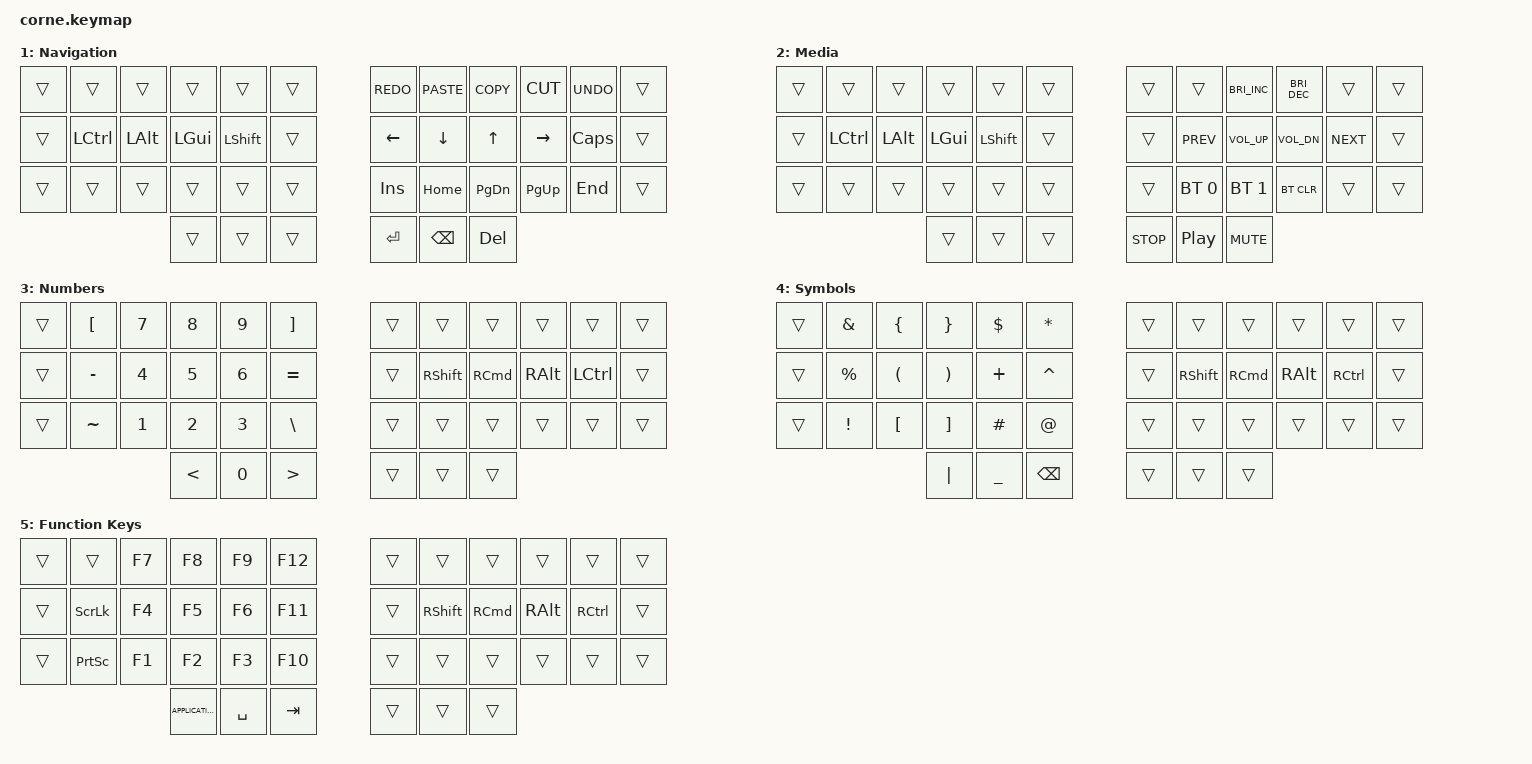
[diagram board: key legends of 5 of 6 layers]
/*
 * Copyright (c) 2020 The ZMK Contributors
 *
 * SPDX-License-Identifier: MIT
 */
// ZMK includes
#include <behaviors.dtsi>
#include <dt-bindings/zmk/bt.h>
#include <dt-bindings/zmk/keys.h>

// Define layers number
#define Base 0
#define Nav 1
#define Media 2
#define Num 3
#define Symbol 4
#define FN 5

/ {
    behaviors {
        // Positional Homerow mods
        // Homerow mods that prevent accidental activations when rolling keys,
        // such as when typing `st` or `ne` on colemak-dh layouts or `as` on
        // qwerty.
        //
        // Works by only allowing a mod to activate within tapping-term if
        // it's on the opposite side of the keyboard or on the same side thumb
        // keys.
        // Further optimization using urob's timerless homerow mods method:
        // https://github.com/urob/zmk-config#timeless-homerow-mods

        hm_l: homerow_mods_left {
            compatible = "zmk,behavior-hold-tap";
            #binding-cells = <3>;
            bindings = <&kp N &kp R &kp T>;

            flavor = "balanced";
            tapping-term-ms = <300>;
            quick-tap-ms = <175>;                // repeat on tap-into-hold
            require-prior-idle-ms = <150>;
            hold-trigger-key-positions = <13 14 15>;

        };

        hm_r: homerow_mods_right {
            compatible = "zmk,behavior-hold-tap";
            #binding-cells = <3>;
            bindings = <&kp A &kp E &kp I>;

            flavor = "balanced";
            tapping-term-ms = <300>;
            quick-tap-ms = <175>;
            require-prior-idle-ms = <150>;
            hold-trigger-key-positions = <20 21 22>;

        };

        // Positional Homerow mods for shift
        // Use faster tapping term and disable some features that may
        // cause false negatives.

        hm_shift_l: hm_shift_l {
            compatible = "zmk,behavior-hold-tap";
            #binding-cells = <1>;
            bindings = <&kp S>;

            flavor = "balanced";
            tapping-term-ms = <200>;
            quick-tap-ms = <175>;
            require-prior-idle-ms = <150>;
            hold-trigger-key-positions = <16>;

        };

        hm_shift_r: hm_shift_r {
            compatible = "zmk,behavior-hold-tap";
            #binding-cells = <1>;
            bindings = <&kp H>;

            flavor = "balanced";
            tapping-term-ms = <200>;
            quick-tap-ms = <175>;
            require-prior-idle-ms = <150>;
            hold-trigger-key-positions = <19>;

        };
    };

    keymap {
        compatible = "zmk,keymap";

        Base_layer {
            display-name = "Base";
            bindings = <
&kp ESC    &kp B          &kp L         &kp D         &kp W                &kp Z      &kp SQT      &kp F                &kp O         &kp U         &kp J          &kp DOUBLE_QUOTES
&kp CAPS   &hm_l LCTRL N  &hm_l LALT R  &hm_l LGUI T  &hm_shift_l LSHFT S  &kp G      &kp Y        &hm_shift_r RSHFT H  &hm_r RGUI A  &hm_r RALT E  &hm_r RCTRL I  &kp SINGLE_QUOTE
&kp GRAVE  &kp Q          &kp X         &kp M         &kp C                &kp V      &kp K        &kp P                &kp R         &kp COMMA     &kp SLASH      &kp SEMI
                                        &lt 2 ESCAPE  &lt 1 BACKSPACE      &kp TAB    &lt 4 ENTER  &lt 3 SPACE          &lt 5 DELETE
            >;
        };

        Nav_layer {
            display-name = "Navigation";
            bindings = <
&trans  &trans     &trans    &trans    &trans     &trans    &kp K_REDO  &kp K_PASTE    &kp K_COPY     &kp K_CUT    &kp K_UNDO  &trans
&trans  &kp LCTRL  &kp LALT  &kp LGUI  &kp LSHFT  &trans    &kp LEFT    &kp DOWN       &kp UP         &kp RIGHT    &kp CAPS    &trans
&trans  &trans     &trans    &trans    &trans     &trans    &kp INSERT  &kp HOME       &kp PAGE_DOWN  &kp PAGE_UP  &kp END     &trans
                             &trans    &trans     &trans    &kp RETURN  &kp BACKSPACE  &kp DELETE
            >;
        };

        Media_layer {
            display-name = "Media";
            bindings = <
&trans  &trans     &trans    &trans    &trans     &trans    &trans      &trans            &kp C_BRIGHTNESS_INC  &kp C_BRIGHTNESS_DEC  &trans      &trans
&trans  &kp LCTRL  &kp LALT  &kp LGUI  &kp LSHFT  &trans    &trans      &kp C_PREV        &kp C_VOL_UP          &kp C_VOL_DN          &kp C_NEXT  &trans
&trans  &trans     &trans    &trans    &trans     &trans    &trans      &bt BT_SEL 0      &bt BT_SEL 1          &bt BT_CLR            &trans      &trans
                             &trans    &trans     &trans    &kp K_STOP  &kp C_PLAY_PAUSE  &kp K_MUTE
            >;
        };

        Num_layer {
            // -----------------------------------------------------------------------------------------
            // |  TAB |  1  |  2  |  3  |  4  |  5  |   |  6  |  7  |  8  |  9  |  0  | BKSP |
            // | BTCLR| BT1 | BT2 | BT3 | BT4 | BT5 |   | LFT | DWN |  UP | RGT |     |      |
            // | SHFT |     |     |     |     |     |   |     |     |     |     |     |      |
            //                    | GUI |     | SPC |   | ENT |     | ALT |

            bindings = <
&trans  &kp LEFT_BRACKET  &kp N7  &kp N8         &kp N9  &kp RIGHT_BRACKET    &trans  &trans           &trans             &trans         &trans            &trans
&trans  &kp MINUS         &kp N4  &kp N5         &kp N6  &kp EQUAL            &trans  &kp RIGHT_SHIFT  &kp RIGHT_COMMAND  &kp RIGHT_ALT  &kp LEFT_CONTROL  &trans
&trans  &kp TILDE         &kp N1  &kp N2         &kp N3  &kp BSLH             &trans  &trans           &trans             &trans         &trans            &trans
                                  &kp LESS_THAN  &kp N0  &kp GREATER_THAN     &trans  &trans           &trans
            >;

            label = "Numbers";
        };

        Symbol_layer {
            // -----------------------------------------------------------------------------------------
            // |  TAB |  !  |  @  |  #  |  $  |  %  |   |  ^  |  &  |  *  |  (  |  )  | BKSP |
            // | CTRL |     |     |     |     |     |   |  -  |  =  |  [  |  ]  |  \  |  `   |
            // | SHFT |     |     |     |     |     |   |  _  |  +  |  {  |  }  | "|" |  ~   |
            //                    | GUI |     | SPC |   | ENT |     | ALT |

            bindings = <
&trans  &kp AMPERSAND    &kp LEFT_BRACE        &kp RIGHT_BRACE        &kp DLLR        &kp ASTERISK     &trans  &trans           &trans             &trans         &trans             &trans
&trans  &kp PERCENT      &kp LEFT_PARENTHESIS  &kp RIGHT_PARENTHESIS  &kp PLUS        &kp CARET        &trans  &kp RIGHT_SHIFT  &kp RIGHT_COMMAND  &kp RIGHT_ALT  &kp RIGHT_CONTROL  &trans
&trans  &kp EXCLAMATION  &kp LEFT_BRACKET      &kp RIGHT_BRACKET      &kp POUND       &kp AT_SIGN      &trans  &trans           &trans             &trans         &trans             &trans
                                               &kp PIPE               &kp UNDERSCORE  &kp BACKSPACE    &trans  &trans           &trans
            >;

            label = "Symbols";
        };

        FN_layer {
            label = "Function Keys";
            bindings = <
&trans  &trans           &kp F7  &kp F8             &kp F9     &kp F12    &trans  &trans           &trans             &trans         &trans             &trans
&trans  &kp SCROLLLOCK   &kp F4  &kp F5             &kp F6     &kp F11    &trans  &kp RIGHT_SHIFT  &kp RIGHT_COMMAND  &kp RIGHT_ALT  &kp RIGHT_CONTROL  &trans
&trans  &kp PRINTSCREEN  &kp F1  &kp F2             &kp F3     &kp F10    &trans  &trans           &trans             &trans         &trans             &trans
                                 &kp K_APPLICATION  &kp SPACE  &kp TAB    &trans  &trans           &trans
            >;
        };
    };
};
